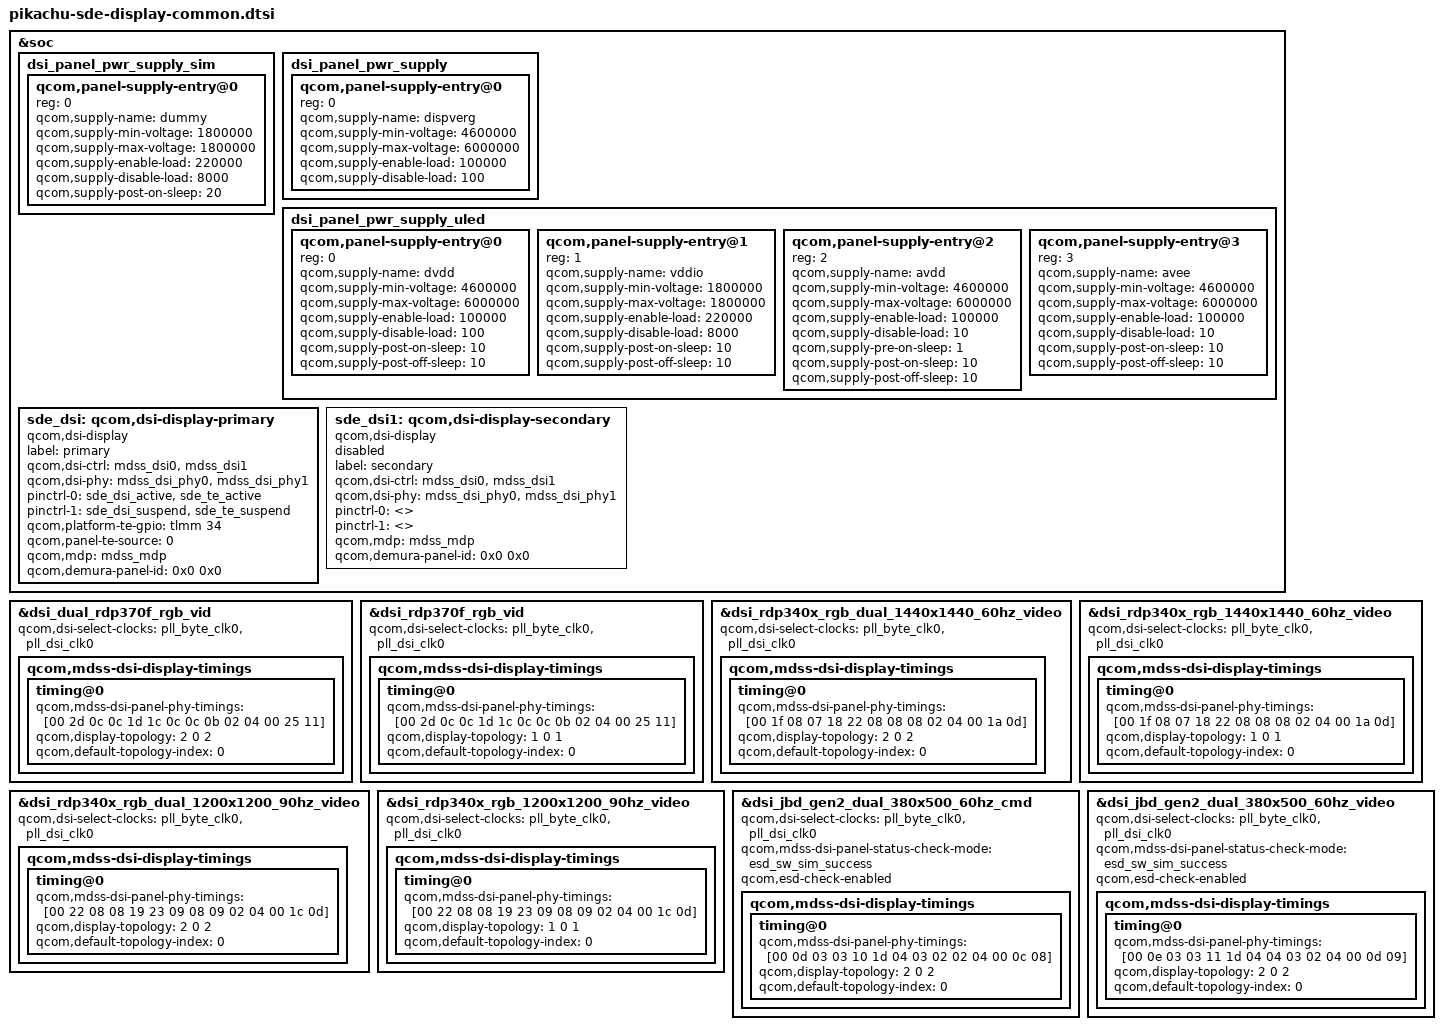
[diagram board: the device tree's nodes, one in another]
// SPDX-License-Identifier: BSD-3-Clause
/*
 * Copyright (c) Qualcomm Technologies, Inc. and/or its subsidiaries.
 */

#include "dsi-panel-dual-rdp370f-rgb-video.dtsi"
#include "dsi-panel-rdp340x-rgb-dual-1440x1440-60hz-video.dtsi"
#include "dsi-panel-rdp340x-rgb-dual-1200x1200-90hz-video.dtsi"
#include "dsi-panel-rdp370f-rgb-video.dtsi"
#include "dsi-panel-rdp340x-rgb-1440x1440-60hz-video.dtsi"
#include "dsi-panel-rdp340x-rgb-1200x1200-90hz-video.dtsi"
#include "dsi-panel-jbd-gen2-dual-380x500-60hz-cmd.dtsi"
#include "dsi-panel-jbd-gen2-dual-380x500-60hz-video.dtsi"

#include "pikachu-sde-display-pinctrl.dtsi"

&soc {
	dsi_panel_pwr_supply_sim: dsi_panel_pwr_supply_sim {
		#address-cells = <1>;
		#size-cells = <0>;

		qcom,panel-supply-entry@0 {
			reg = <0>;
			qcom,supply-name = "dummy";
			qcom,supply-min-voltage = <1800000>;
			qcom,supply-max-voltage = <1800000>;
			qcom,supply-enable-load = <220000>;
			qcom,supply-disable-load = <8000>;
			qcom,supply-post-on-sleep = <20>;
		};
	};

	dsi_panel_pwr_supply: dsi_panel_pwr_supply {
		#address-cells = <1>;
		#size-cells = <0>;

		qcom,panel-supply-entry@0 {
			reg = <0>;
			qcom,supply-name = "dispverg";
			qcom,supply-min-voltage = <4600000>;
			qcom,supply-max-voltage = <6000000>;
			qcom,supply-enable-load = <100000>;
			qcom,supply-disable-load = <100>;
		};
	};

	dsi_panel_pwr_supply_uled: dsi_panel_pwr_supply_uled {
		#address-cells = <1>;
		#size-cells = <0>;

		qcom,panel-supply-entry@0 {
			reg = <0>;
			qcom,supply-name = "dvdd";
			qcom,supply-min-voltage = <4600000>;
			qcom,supply-max-voltage = <6000000>;
			qcom,supply-enable-load = <100000>;
			qcom,supply-disable-load = <100>;
			qcom,supply-post-on-sleep = <10>;
			qcom,supply-post-off-sleep = <10>;
		};

		qcom,panel-supply-entry@1 {
			reg = <1>;
			qcom,supply-name = "vddio";
			qcom,supply-min-voltage = <1800000>;
			qcom,supply-max-voltage = <1800000>;
			qcom,supply-enable-load = <220000>;
			qcom,supply-disable-load = <8000>;
			qcom,supply-post-on-sleep = <10>;
			qcom,supply-post-off-sleep = <10>;
		};
		qcom,panel-supply-entry@2 {
			reg = <2>;
			qcom,supply-name = "avdd";
			qcom,supply-min-voltage = <4600000>;
			qcom,supply-max-voltage = <6000000>;
			qcom,supply-enable-load = <100000>;
			qcom,supply-disable-load = <10>;
			qcom,supply-pre-on-sleep = <1>;
			qcom,supply-post-on-sleep = <10>;
			qcom,supply-post-off-sleep = <10>;
		};

		qcom,panel-supply-entry@3 {
			reg = <3>;
			qcom,supply-name = "avee";
			qcom,supply-min-voltage = <4600000>;
			qcom,supply-max-voltage = <6000000>;
			qcom,supply-enable-load = <100000>;
			qcom,supply-disable-load = <10>;
			qcom,supply-post-on-sleep = <10>;
			qcom,supply-post-off-sleep = <10>;
		};
	};

	sde_dsi: qcom,dsi-display-primary {
		compatible = "qcom,dsi-display";
		label = "primary";

		qcom,dsi-ctrl = <&mdss_dsi0 &mdss_dsi1>;
		qcom,dsi-phy = <&mdss_dsi_phy0 &mdss_dsi_phy1>;

		pinctrl-names = "panel_active", "panel_suspend";
		pinctrl-0 = <&sde_dsi_active &sde_te_active>;
		pinctrl-1 = <&sde_dsi_suspend &sde_te_suspend>;

		qcom,platform-te-gpio = <&tlmm 34 0>;
		qcom,panel-te-source = <0>;

		qcom,mdp = <&mdss_mdp>;
		qcom,demura-panel-id = <0x0 0x0>;
	};

	sde_dsi1: qcom,dsi-display-secondary {
		compatible = "qcom,dsi-display";
		label = "secondary";

		qcom,dsi-ctrl = <&mdss_dsi0 &mdss_dsi1>;
		qcom,dsi-phy = <&mdss_dsi_phy0 &mdss_dsi_phy1>;

		pinctrl-names = "panel_active", "panel_suspend";
		pinctrl-0 = <>;
		pinctrl-1 = <>;

		qcom,mdp = <&mdss_mdp>;
		qcom,demura-panel-id = <0x0 0x0>;

		status = "disabled";
	};
};

&dsi_dual_rdp370f_rgb_vid {
	qcom,dsi-select-clocks = "pll_byte_clk0", "pll_dsi_clk0";

	qcom,mdss-dsi-display-timings {
		timing@0 {
			qcom,mdss-dsi-panel-phy-timings = [00 2d 0c 0c 1d 1c 0c
				0c 0b 02 04 00 25 11];
			qcom,display-topology = <2 0 2>;
			qcom,default-topology-index = <0>;
		};
	};
};

&dsi_rdp370f_rgb_vid {
	qcom,dsi-select-clocks = "pll_byte_clk0", "pll_dsi_clk0";

	qcom,mdss-dsi-display-timings {
		timing@0 {
			qcom,mdss-dsi-panel-phy-timings = [00 2d 0c 0c 1d 1c 0c
				0c 0b 02 04 00 25 11];
			qcom,display-topology = <1 0 1>;
			qcom,default-topology-index = <0>;
		};
	};
};

&dsi_rdp340x_rgb_dual_1440x1440_60hz_video {
	qcom,dsi-select-clocks = "pll_byte_clk0", "pll_dsi_clk0";

	qcom,mdss-dsi-display-timings {
		timing@0 {
			qcom,mdss-dsi-panel-phy-timings = [00 1f 08 07 18 22 08
				08 08 02 04 00 1a 0d];
			qcom,display-topology = <2 0 2>;
			qcom,default-topology-index = <0>;
		};
	};
};

&dsi_rdp340x_rgb_1440x1440_60hz_video {
	qcom,dsi-select-clocks = "pll_byte_clk0", "pll_dsi_clk0";

	qcom,mdss-dsi-display-timings {
		timing@0 {
			qcom,mdss-dsi-panel-phy-timings = [00 1f 08 07 18 22 08
				08 08 02 04 00 1a 0d];
			qcom,display-topology = <1 0 1>;
			qcom,default-topology-index = <0>;
		};
	};
};

&dsi_rdp340x_rgb_dual_1200x1200_90hz_video {
	qcom,dsi-select-clocks = "pll_byte_clk0", "pll_dsi_clk0";

	qcom,mdss-dsi-display-timings {
		timing@0 {
			qcom,mdss-dsi-panel-phy-timings = [00 22 08 08 19 23 09
				08 09 02 04 00 1c 0d];
			qcom,display-topology = <2 0 2>;
			qcom,default-topology-index = <0>;
		};
	};
};

&dsi_rdp340x_rgb_1200x1200_90hz_video {
	qcom,dsi-select-clocks = "pll_byte_clk0", "pll_dsi_clk0";

	qcom,mdss-dsi-display-timings {
		timing@0 {
			qcom,mdss-dsi-panel-phy-timings = [00 22 08 08 19 23 09
				08 09 02 04 00 1c 0d];
			qcom,display-topology = <1 0 1>;
			qcom,default-topology-index = <0>;
		};
	};
};


&dsi_jbd_gen2_dual_380x500_60hz_cmd {
	qcom,dsi-select-clocks = "pll_byte_clk0", "pll_dsi_clk0";
	qcom,mdss-dsi-panel-status-check-mode = "esd_sw_sim_success";
	qcom,esd-check-enabled;

	qcom,mdss-dsi-display-timings {
		timing@0 {
			qcom,mdss-dsi-panel-phy-timings = [00 0d 03 03 10 1d 04
				03 02 02 04 00 0c 08];
			qcom,display-topology = <2 0 2>;
			qcom,default-topology-index = <0>;
		};
	};
};

&dsi_jbd_gen2_dual_380x500_60hz_video {
	qcom,dsi-select-clocks = "pll_byte_clk0", "pll_dsi_clk0";
	qcom,mdss-dsi-panel-status-check-mode = "esd_sw_sim_success";
	qcom,esd-check-enabled;

	qcom,mdss-dsi-display-timings {
		timing@0 {
			//qcom,mdss-dsi-panel-phy-timings = [00 0d 03 03 10 1d 04
			//	03 02 02 04 00 0c 08];
			// SVE CMD mode
			qcom,mdss-dsi-panel-phy-timings = [00 0e 03 03 11 1d 04
				04 03 02 04 00 0d 09];
			qcom,display-topology = <2 0 2>;
			qcom,default-topology-index = <0>;
		};
	};
};
